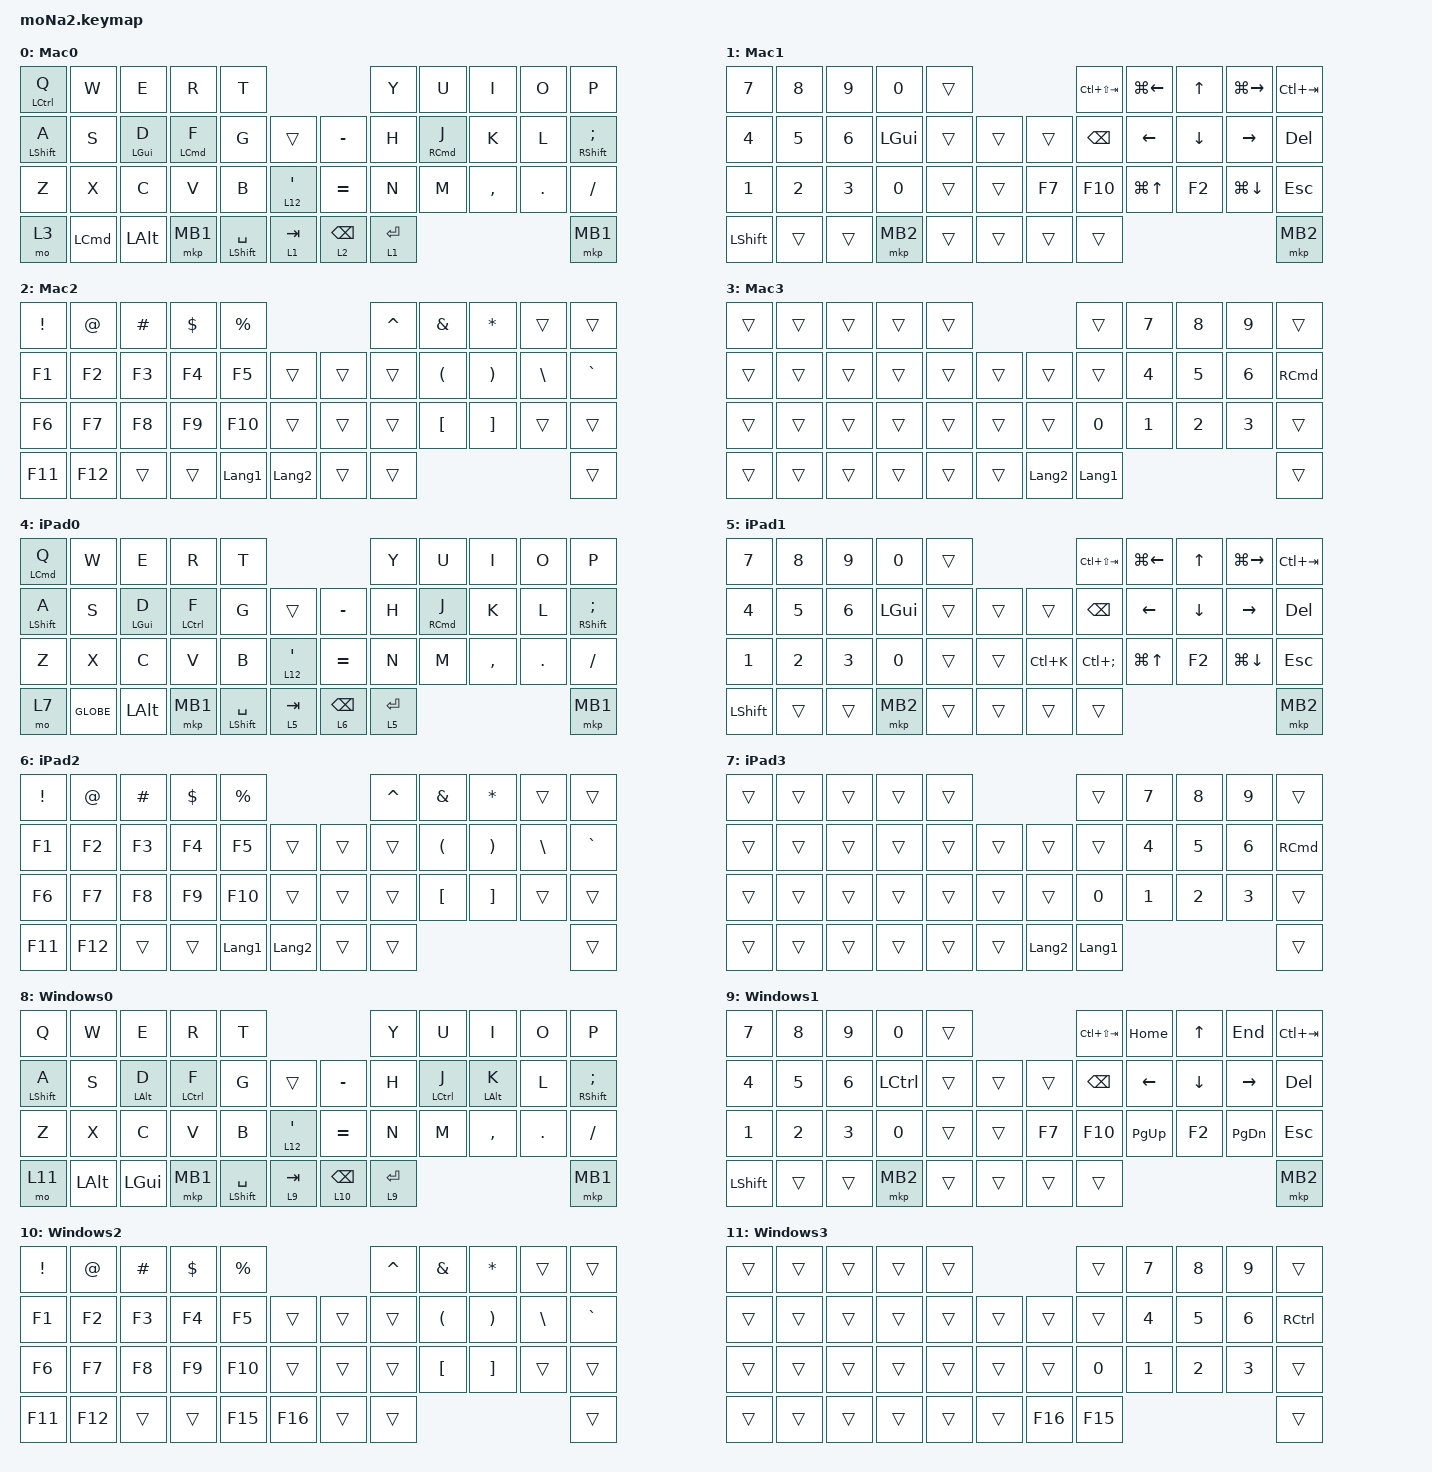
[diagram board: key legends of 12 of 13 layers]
#include <behaviors.dtsi>
#include <dt-bindings/zmk/bt.h>
#include <dt-bindings/zmk/keys.h>
#include <dt-bindings/zmk/pointing.h>

#define ZMK_POINTING_DEFAULT_SCRL_VAL 100
#define MOUSE 6

&mt {
    flavor = "balanced";
    quick-tap-ms = <200>;
    tapping-term-ms = <180>;
    require-prior-idle-ms = <150>;
};

&lt {
    quick-tap-ms = <175>;
    tapping-term-ms = <165>;
};

/ {
    combos {
        compatible = "zmk,combos";

        alt_f4 {
            bindings = <&kp RA(F4)>;
            key-positions = <0 9>;
            timeout-ms = <201>;
            layers = <8>;
        };
    };

    macros {
        to_layer_0: to_layer_0 {
            compatible = "zmk,behavior-macro-one-param";
            #binding-cells = <1>;
            bindings = <&to 0 &macro_param_1to1 &kp MACRO_PLACEHOLDER>;
            label = "TO_LAYER_0";
        };

        Bluetooth0: Bluetooth0 {
            compatible = "zmk,behavior-macro";
            #binding-cells = <0>;
            bindings = <&bt BT_SEL 0 &to 0>, <&macro_press>;

            label = "BLUETOOTH0";
        };

        Bluetooth1: Bluetooth1 {
            compatible = "zmk,behavior-macro";
            #binding-cells = <0>;
            bindings = <&bt BT_SEL 1 &to 4>, <&macro_press>;

            label = "BLUETOOTH1";
        };

        Bluetooth2: Bluetooth2 {
            compatible = "zmk,behavior-macro";
            #binding-cells = <0>;
            bindings = <&bt BT_SEL 2 &to 8>, <&macro_press>;

            label = "BLUETOOTH2";
        };

        Bluetooth3: Bluetooth3 {
            compatible = "zmk,behavior-macro";
            #binding-cells = <0>;
            bindings = <&bt BT_SEL 3 &to 8>, <&macro_press>;

            label = "NEW_MACRO";
        };

        Bluetooth4: Bluetooth4 {
            compatible = "zmk,behavior-macro";
            #binding-cells = <0>;
            bindings = <&bt BT_SEL 4 &to 8>, <&macro_press>;

            label = "NEW_MACRO";
        };
    };

    behaviors {
        lt_to_layer_0: lt_to_layer_0 {
            compatible = "zmk,behavior-hold-tap";
            label = "LAYER_TAP_TO_0";
            bindings = <&mo>, <&to_layer_0>;

            #binding-cells = <2>;
            tapping-term-ms = <200>;
        };

        scroll_up_down: behavior_sensor_rotate_mouse_wheel_up_down {
            compatible = "zmk,behavior-sensor-rotate";
            #sensor-binding-cells = <0>;
            bindings = <&msc SCRL_UP>, <&msc SCRL_DOWN>;

            tap-ms = <20>;
        };
    };

    keymap {
        compatible = "zmk,keymap";

        Mac0 {
            bindings = <
&mt LEFT_CONTROL Q  &kp W             &kp E           &kp R               &kp T                                                         &kp Y        &kp U                &kp I      &kp O    &kp P
&mt LEFT_SHIFT A    &kp S             &mt LEFT_GUI D  &mt LEFT_COMMAND F  &kp G                 &trans                 &kp MINUS        &kp H        &mt RIGHT_COMMAND J  &kp K      &kp L    &mt RIGHT_SHIFT SEMICOLON
&kp Z               &kp X             &kp C           &kp V               &kp B                 &lt 12 SINGLE_QUOTE    &kp EQUAL        &kp N        &kp M                &kp COMMA  &kp DOT  &kp SLASH
&mo 3               &kp LEFT_COMMAND  &kp LEFT_ALT    &mkp MB1            &mt LEFT_SHIFT SPACE  &lt 1 TAB              &lt 2 BACKSPACE  &lt 1 ENTER                                           &mkp MB1
            >;

            sensor-bindings =
                <&scroll_up_down>,
                <&inc_dec_kp C_VOL_DN C_VOL_UP>;
        };

        Mac1 {
            bindings = <
&kp NUMBER_7    &kp NUMBER_8  &kp NUMBER_9  &kp NUMBER_0  &trans                    &kp LC(LS(TAB))  &kp LG(LEFT)      &kp UP_ARROW    &kp LG(RIGHT)       &kp LC(TAB)
&kp NUMBER_4    &kp NUMBER_5  &kp NUMBER_6  &kp LEFT_GUI  &trans  &trans    &trans  &kp BACKSPACE    &kp LEFT_ARROW    &kp DOWN_ARROW  &kp RIGHT_ARROW     &kp DELETE
&kp NUMBER_1    &kp NUMBER_2  &kp NUMBER_3  &kp NUMBER_0  &trans  &trans    &kp F7  &kp F10          &kp LG(UP_ARROW)  &kp F2          &kp LG(DOWN_ARROW)  &kp ESCAPE
&kp LEFT_SHIFT  &trans        &trans        &mkp MB2      &trans  &trans    &trans  &trans                                                                 &mkp MB2
            >;

            sensor-bindings = <&inc_dec_kp LG(MINUS) LG(EQUAL)>;
        };

        Mac2 {
            bindings = <
&kp EXCLAMATION  &kp AT_SIGN  &kp HASH  &kp DOLLAR  &kp PERCENT                               &kp CARET  &kp AMPERSAND         &kp ASTRK              &trans         &trans
&kp F1           &kp F2       &kp F3    &kp F4      &kp F5          &trans            &trans  &trans     &kp LEFT_PARENTHESIS  &kp RIGHT_PARENTHESIS  &kp BACKSLASH  &kp GRAVE
&kp F6           &kp F7       &kp F8    &kp F9      &kp F10         &trans            &trans  &trans     &kp LEFT_BRACKET      &kp RIGHT_BRACKET      &trans         &trans
&kp F11          &kp F12      &trans    &trans      &kp LANGUAGE_1  &kp LANGUAGE_2    &trans  &trans                                                                 &trans
            >;

            sensor-bindings = <&inc_dec_kp C_VOLUME_DOWN C_VOLUME_UP>;
        };

        Mac3 {
            bindings = <
&trans  &trans  &trans  &trans  &trans                            &trans          &kp NUMBER_7  &kp NUMBER_8  &kp NUMBER_9  &trans
&trans  &trans  &trans  &trans  &trans  &trans    &trans          &trans          &kp NUMBER_4  &kp NUMBER_5  &kp NUMBER_6  &kp RIGHT_COMMAND
&trans  &trans  &trans  &trans  &trans  &trans    &trans          &kp NUMBER_0    &kp NUMBER_1  &kp NUMBER_2  &kp NUMBER_3  &trans
&trans  &trans  &trans  &trans  &trans  &trans    &kp LANGUAGE_2  &kp LANGUAGE_1                                            &trans
            >;
        };

        iPad0 {
            bindings = <
&mt LEFT_COMMAND Q  &kp W      &kp E           &kp R        &kp T                                                         &kp Y        &kp U                &kp I      &kp O    &kp P
&mt LEFT_SHIFT A    &kp S      &mt LEFT_GUI D  &mt LCTRL F  &kp G                 &trans                 &kp MINUS        &kp H        &mt RIGHT_COMMAND J  &kp K      &kp L    &mt RIGHT_SHIFT SEMICOLON
&kp Z               &kp X      &kp C           &kp V        &kp B                 &lt 12 SINGLE_QUOTE    &kp EQUAL        &kp N        &kp M                &kp COMMA  &kp DOT  &kp SLASH
&mo 7               &kp GLOBE  &kp LEFT_ALT    &mkp MB1     &mt LEFT_SHIFT SPACE  &lt 5 TAB              &lt 6 BACKSPACE  &lt 5 ENTER                                           &mkp MB1
            >;

            sensor-bindings =
                <&scroll_up_down>,
                <&inc_dec_kp C_VOL_DN C_VOL_UP>;
        };

        iPad1 {
            bindings = <
&kp NUMBER_7    &kp NUMBER_8  &kp NUMBER_9  &kp NUMBER_0  &trans                       &kp LC(LS(TAB))    &kp LG(LEFT)      &kp UP_ARROW    &kp LG(RIGHT)       &kp LC(TAB)
&kp NUMBER_4    &kp NUMBER_5  &kp NUMBER_6  &kp LEFT_GUI  &trans  &trans    &trans     &kp BACKSPACE      &kp LEFT_ARROW    &kp DOWN_ARROW  &kp RIGHT_ARROW     &kp DELETE
&kp NUMBER_1    &kp NUMBER_2  &kp NUMBER_3  &kp NUMBER_0  &trans  &trans    &kp LC(K)  &kp LC(SEMICOLON)  &kp LG(UP_ARROW)  &kp F2          &kp LG(DOWN_ARROW)  &kp ESCAPE
&kp LEFT_SHIFT  &trans        &trans        &mkp MB2      &trans  &trans    &trans     &trans                                                                   &mkp MB2
            >;

            sensor-bindings = <&inc_dec_kp LG(MINUS) LG(EQUAL)>;
        };

        iPad2 {
            bindings = <
&kp EXCLAMATION  &kp AT_SIGN  &kp HASH  &kp DOLLAR  &kp PERCENT                               &kp CARET  &kp AMPERSAND         &kp ASTRK              &trans         &trans
&kp F1           &kp F2       &kp F3    &kp F4      &kp F5          &trans            &trans  &trans     &kp LEFT_PARENTHESIS  &kp RIGHT_PARENTHESIS  &kp BACKSLASH  &kp GRAVE
&kp F6           &kp F7       &kp F8    &kp F9      &kp F10         &trans            &trans  &trans     &kp LEFT_BRACKET      &kp RIGHT_BRACKET      &trans         &trans
&kp F11          &kp F12      &trans    &trans      &kp LANGUAGE_1  &kp LANGUAGE_2    &trans  &trans                                                                 &trans
            >;

            sensor-bindings = <&inc_dec_kp C_VOLUME_DOWN C_VOLUME_UP>;
        };

        iPad3 {
            bindings = <
&trans  &trans  &trans  &trans  &trans                            &trans          &kp NUMBER_7  &kp NUMBER_8  &kp NUMBER_9  &trans
&trans  &trans  &trans  &trans  &trans  &trans    &trans          &trans          &kp NUMBER_4  &kp NUMBER_5  &kp NUMBER_6  &kp RIGHT_COMMAND
&trans  &trans  &trans  &trans  &trans  &trans    &trans          &kp NUMBER_0    &kp NUMBER_1  &kp NUMBER_2  &kp NUMBER_3  &trans
&trans  &trans  &trans  &trans  &trans  &trans    &kp LANGUAGE_2  &kp LANGUAGE_1                                            &trans
            >;
        };

        Windows0 {
            bindings = <
&kp Q             &kp W         &kp E           &kp R        &kp T                                                          &kp Y        &kp U        &kp I       &kp O    &kp P
&mt LEFT_SHIFT A  &kp S         &mt LEFT_ALT D  &mt LCTRL F  &kp G                 &trans                 &kp MINUS         &kp H        &mt LCTRL J  &mt LALT K  &kp L    &mt RIGHT_SHIFT SEMICOLON
&kp Z             &kp X         &kp C           &kp V        &kp B                 &lt 12 SINGLE_QUOTE    &kp EQUAL         &kp N        &kp M        &kp COMMA   &kp DOT  &kp SLASH
&mo 11            &kp LEFT_ALT  &kp LEFT_GUI    &mkp MB1     &mt LEFT_SHIFT SPACE  &lt 9 TAB              &lt 10 BACKSPACE  &lt 9 ENTER                                    &mkp MB1
            >;

            sensor-bindings =
                <&scroll_up_down>,
                <&inc_dec_kp C_VOL_DN C_VOL_UP>;
        };

        Windows1 {
            bindings = <
&kp NUMBER_7    &kp NUMBER_8  &kp NUMBER_9  &kp NUMBER_0      &trans                    &kp LC(LS(TAB))  &kp HOME        &kp UP_ARROW    &kp END          &kp LC(TAB)
&kp NUMBER_4    &kp NUMBER_5  &kp NUMBER_6  &kp LEFT_CONTROL  &trans  &trans    &trans  &kp BACKSPACE    &kp LEFT_ARROW  &kp DOWN_ARROW  &kp RIGHT_ARROW  &kp DELETE
&kp NUMBER_1    &kp NUMBER_2  &kp NUMBER_3  &kp NUMBER_0      &trans  &trans    &kp F7  &kp F10          &kp PAGE_UP     &kp F2          &kp PAGE_DOWN    &kp ESCAPE
&kp LEFT_SHIFT  &trans        &trans        &mkp MB2          &trans  &trans    &trans  &trans                                                            &mkp MB2
            >;

            sensor-bindings = <&inc_dec_kp LC(MINUS) LC(PLUS)>;
        };

        Windows2 {
            bindings = <
&kp EXCLAMATION  &kp AT_SIGN  &kp HASH  &kp DOLLAR  &kp PERCENT                     &kp CARET  &kp AMPERSAND         &kp ASTRK              &trans         &trans
&kp F1           &kp F2       &kp F3    &kp F4      &kp F5       &trans     &trans  &trans     &kp LEFT_PARENTHESIS  &kp RIGHT_PARENTHESIS  &kp BACKSLASH  &kp GRAVE
&kp F6           &kp F7       &kp F8    &kp F9      &kp F10      &trans     &trans  &trans     &kp LEFT_BRACKET      &kp RIGHT_BRACKET      &trans         &trans
&kp F11          &kp F12      &trans    &trans      &kp F15      &kp F16    &trans  &trans                                                                 &trans
            >;

            sensor-bindings = <&inc_dec_kp C_VOLUME_DOWN C_VOLUME_UP>;
        };

        Windows3 {
            bindings = <
&trans  &trans  &trans  &trans  &trans                     &trans        &kp NUMBER_7  &kp NUMBER_8  &kp NUMBER_9  &trans
&trans  &trans  &trans  &trans  &trans  &trans    &trans   &trans        &kp NUMBER_4  &kp NUMBER_5  &kp NUMBER_6  &kp RCTRL
&trans  &trans  &trans  &trans  &trans  &trans    &trans   &kp NUMBER_0  &kp NUMBER_1  &kp NUMBER_2  &kp NUMBER_3  &trans
&trans  &trans  &trans  &trans  &trans  &trans    &kp F16  &kp F15                                                 &trans
            >;
        };

        Bluetooth {
            bindings = <
&trans  &trans  &trans  &trans  &trans                         &trans  &trans       &trans       &trans       &Bluetooth4
&trans  &trans  &trans  &trans  &trans  &trans    &trans       &trans  &Bluetooth0  &Bluetooth1  &Bluetooth2  &Bluetooth3
&trans  &trans  &trans  &trans  &trans  &trans    &bootloader  &trans  &trans       &trans       &trans       &bt BT_CLR
&trans  &trans  &trans  &trans  &trans  &trans    &trans       &trans                                         &bt BT_CLR_ALL
            >;

            sensor-bindings = <&scroll_up_down>;
        };
    };
};
